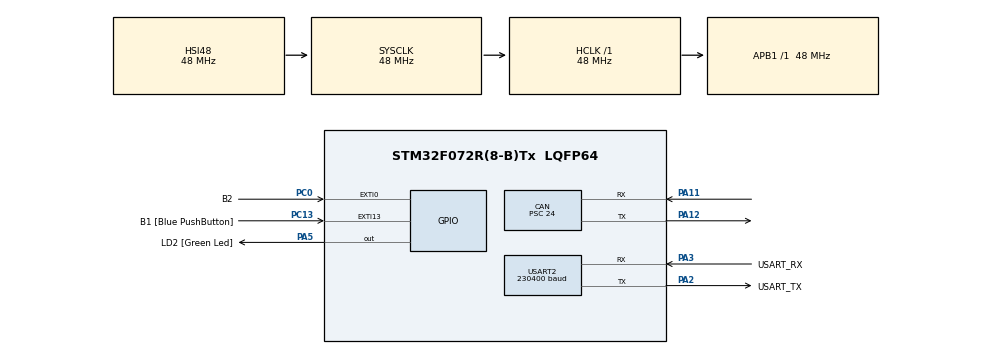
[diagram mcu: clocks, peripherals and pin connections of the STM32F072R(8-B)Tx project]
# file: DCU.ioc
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CAN.BS1=CAN_BS1_5TQ
CAN.BS2=CAN_BS2_2TQ
CAN.CalculateTimeQuantum=500.0
CAN.Prescaler=24
Dma.Request0=USART2_RX
Dma.USART2_RX.0.Direction=DMA_PERIPH_TO_MEMORY
Dma.USART2_RX.0.Instance=DMA1_Channel5
Dma.USART2_RX.0.MemDataAlignment=DMA_MDATAALIGN_BYTE
Dma.USART2_RX.0.MemInc=DMA_MINC_ENABLE
Dma.USART2_RX.0.Mode=DMA_CIRCULAR
Dma.USART2_RX.0.PeriphDataAlignment=DMA_PDATAALIGN_BYTE
Dma.USART2_RX.0.PeriphInc=DMA_PINC_DISABLE
Dma.USART2_RX.0.Priority=DMA_PRIORITY_LOW
FREERTOS.Tasks01=mainTask,0,256,mainTaskFunction,As weak,NULL,Dynamic,NULL,NULL;canSendTask,3,256,canTask,As weak,NULL,Dynamic,NULL,NULL
FREERTOS.configCHECK_FOR_STACK_OVERFLOW=2
FREERTOS.configGENERATE_RUN_TIME_STATS=1
FREERTOS.configTIMER_QUEUE_LENGTH=2
FREERTOS.configTIMER_TASK_STACK_DEPTH=128
FREERTOS.configTOTAL_HEAP_SIZE=8192
FREERTOS.configUSE_COUNTING_SEMAPHORES=1
FREERTOS.configUSE_STATS_FORMATTING_FUNCTIONS=1
FREERTOS.configUSE_TIMERS=1
FREERTOS.configUSE_TRACE_FACILITY=1
Mcu.Family=STM32F0
Mcu.Name=STM32F072R(8-B)Tx
Mcu.Package=LQFP64
NVIC.CEC_CAN_IRQn=true\:3\:0\:false\:false\:true\:true\:true\:true
NVIC.DMA1_Channel4_5_6_7_IRQn=true\:3\:0\:false\:false\:true\:true\:false\:true
NVIC.EXTI0_1_IRQn=true\:3\:0\:false\:false\:true\:true\:true\:true
NVIC.EXTI4_15_IRQn=true\:3\:0\:false\:false\:true\:true\:true\:true
NVIC.USART2_IRQn=true\:3\:0\:false\:false\:true\:true\:true\:true
PA11.Mode=Master
PA11.Signal=CAN_RX
PA12.Mode=Master
PA12.Signal=CAN_TX
PA13.GPIO_Label=TMS
PA13.Mode=Serial_Wire
PA13.Signal=SYS_SWDIO
PA14.GPIO_Label=TCK
PA14.Mode=Serial_Wire
PA14.Signal=SYS_SWCLK
PA2.GPIO_Label=USART_TX
PA2.GPIO_Mode=GPIO_MODE_AF_PP
PA2.GPIO_PuPd=GPIO_NOPULL
PA2.GPIO_Speed=GPIO_SPEED_FREQ_LOW
PA2.Mode=Asynchronous
PA2.Signal=USART2_TX
PA3.GPIO_Label=USART_RX
PA3.GPIO_Mode=GPIO_MODE_AF_PP
PA3.GPIO_PuPd=GPIO_NOPULL
PA3.GPIO_Speed=GPIO_SPEED_FREQ_LOW
PA3.Mode=Asynchronous
PA3.Signal=USART2_RX
PA5.GPIO_Label=LD2 [Green Led]
PA5.GPIO_Mode=GPIO_MODE_OUTPUT_PP
PA5.GPIO_PuPd=GPIO_NOPULL
PA5.GPIO_Speed=GPIO_SPEED_FREQ_LOW
PA5.Signal=GPIO_Output
PC0.GPIO_Label=B2
PC0.GPIO_ModeDefaultEXTI=GPIO_MODE_IT_FALLING
PC0.GPIO_PuPd=GPIO_PULLUP
PC0.Signal=GPXTI0
PC13.GPIO_Label=B1 [Blue PushButton]
PC13.GPIO_ModeDefaultEXTI=GPIO_MODE_IT_FALLING
PC13.Signal=GPXTI13
PC14-OSC32_IN.Mode=LSE-External-Oscillator
PC14-OSC32_IN.Signal=RCC_OSC32_IN
PC15-OSC32_OUT.Mode=LSE-External-Oscillator
PC15-OSC32_OUT.Signal=RCC_OSC32_OUT
PF0-OSC_IN.Mode=HSE-External-Clock-Source
PF0-OSC_IN.Signal=RCC_OSC_IN
PF1-OSC_OUT.Signal=RCC_OSC_OUT
ProjectManager.HeapSize=0x200
ProjectManager.StackSize=0x400
ProjectManager.TargetToolchain=Makefile
RCC.AHBFreq_Value=48000000
RCC.APB1Freq_Value=48000000
RCC.APB1TimFreq_Value=48000000
RCC.FLatency-AdvancedSettings=FLASH_LATENCY_1
RCC.HCLKFreq_Value=48000000
RCC.PLLDivider=RCC_PREDIV_DIV2
RCC.PLLMUL=RCC_PLL_MUL12
RCC.PREFETCH_ENABLE-AdvancedSettings=1
RCC.SYSCLKFreq_VALUE=48000000
RCC.SYSCLKSource=RCC_SYSCLKSOURCE_HSI48
USART2.BaudRate=230400
USART2.VirtualMode=VM_ASYNC
USART2.VirtualMode-Asynchronous=VM_ASYNC
VP_FREERTOS_VS_CMSIS_V1.Mode=CMSIS_V1
VP_IWDG_VS_IWDG.Mode=IWDG_Activate
VP_TIM2_VS_ClockSourceINT.Mode=Internal
board=NUCLEO-F072RB

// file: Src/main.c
/* USER CODE BEGIN Header */
/**
  ******************************************************************************
  * @file           : main.c
  * @brief          : Main program body
  ******************************************************************************
  * @attention
  *
  * <h2><center>&copy; Copyright (c) 2020 STMicroelectronics.
  * All rights reserved.</center></h2>
  *
  * This software component is licensed by ST under Ultimate Liberty license
  * SLA0044, the "License"; You may not use this file except in compliance with
  * the License. You may obtain a copy of the License at:
  *                             www.st.com/SLA0044
  *
  ******************************************************************************
  */
/* USER CODE END Header */

#include "main.h"
#include "cmsis_os.h"
#include "can.h"
#include "dma.h"
#include "iwdg.h"
#include "tim.h"
#include "usart.h"
#include "gpio.h"

/* USER CODE BEGIN Includes */
#include "stdio.h"
#include "generalErrorHandler.h"
/* USER CODE END Includes */

/* USER CODE BEGIN PV */
/* Private variables ---------------------------------------------------------*/

/* USER CODE END PV */

void SystemClock_Config(void);
void MX_FREERTOS_Init(void);
/* USER CODE BEGIN PFP */
/* Private function prototypes -----------------------------------------------*/
__weak void userInit() {}
/* USER CODE END PFP */

int main(void)
{

  /* MCU Configuration--------------------------------------------------------*/

  /* Reset of all peripherals, Initializes the Flash interface and the Systick. */
  HAL_Init();

  /* Configure the system clock */
  SystemClock_Config();

  /* Initialize all configured peripherals */
  MX_GPIO_Init();
  MX_DMA_Init();
  MX_USART2_UART_Init();
  MX_CAN_Init();
  MX_TIM2_Init();
  MX_IWDG_Init();
  /* USER CODE BEGIN 2 */
  userInit();
  /* USER CODE END 2 */

  /* Call init function for freertos objects (in freertos.c) */
  MX_FREERTOS_Init();
  /* Start scheduler */
  osKernelStart();

  /* We should never get here as control is now taken by the scheduler */
  /* Infinite loop */
  while (1)
  {

  }
}

void SystemClock_Config(void)
{
  RCC_OscInitTypeDef RCC_OscInitStruct = {0};
  RCC_ClkInitTypeDef RCC_ClkInitStruct = {0};
  RCC_PeriphCLKInitTypeDef PeriphClkInit = {0};

  /** Initializes the CPU, AHB and APB busses clocks
  */
  RCC_OscInitStruct.OscillatorType = RCC_OSCILLATORTYPE_HSI48|RCC_OSCILLATORTYPE_LSI;
  RCC_OscInitStruct.HSI48State = RCC_HSI48_ON;
  RCC_OscInitStruct.LSIState = RCC_LSI_ON;
  RCC_OscInitStruct.PLL.PLLState = RCC_PLL_NONE;
  if (HAL_RCC_OscConfig(&RCC_OscInitStruct) != HAL_OK)
  {
    Error_Handler();
  }
  /** Initializes the CPU, AHB and APB busses clocks
  */
  RCC_ClkInitStruct.ClockType = RCC_CLOCKTYPE_HCLK|RCC_CLOCKTYPE_SYSCLK
                              |RCC_CLOCKTYPE_PCLK1;
  RCC_ClkInitStruct.SYSCLKSource = RCC_SYSCLKSOURCE_HSI48;
  RCC_ClkInitStruct.AHBCLKDivider = RCC_SYSCLK_DIV1;
  RCC_ClkInitStruct.APB1CLKDivider = RCC_HCLK_DIV1;

  if (HAL_RCC_ClockConfig(&RCC_ClkInitStruct, FLASH_LATENCY_1) != HAL_OK)
  {
    Error_Handler();
  }
  PeriphClkInit.PeriphClockSelection = RCC_PERIPHCLK_USART2;
  PeriphClkInit.Usart2ClockSelection = RCC_USART2CLKSOURCE_PCLK1;
  if (HAL_RCCEx_PeriphCLKConfig(&PeriphClkInit) != HAL_OK)
  {
    Error_Handler();
  }
}

void Error_Handler(void)
{
  /* USER CODE BEGIN Error_Handler_Debug */
  /* User can add his own implementation to report the HAL error return state */
  _handleError(__FILE__, __LINE__);

  while(1)
  {
  }
  /* USER CODE END Error_Handler_Debug */
}

#ifdef  USE_FULL_ASSERT
/**
  * @brief  Reports the name of the source file and the source line number
  *         where the assert_param error has occurred.
  * @param  file: pointer to the source file name
  * @param  line: assert_param error line source number
  * @retval None
  */
void assert_failed(uint8_t *file, uint32_t line)
{
  /* USER CODE BEGIN 6 */
  /* User can add his own implementation to report the file name and line number,
     tex: printf("Wrong parameters value: file %s on line %d\r\n", file, line) */
  printf("Wrong parameters value: file %s on line %ld\r\n", file, line);
  /* USER CODE END 6 */
}
#endif /* USE_FULL_ASSERT */

/************************ (C) COPYRIGHT STMicroelectronics *****END OF FILE****/
